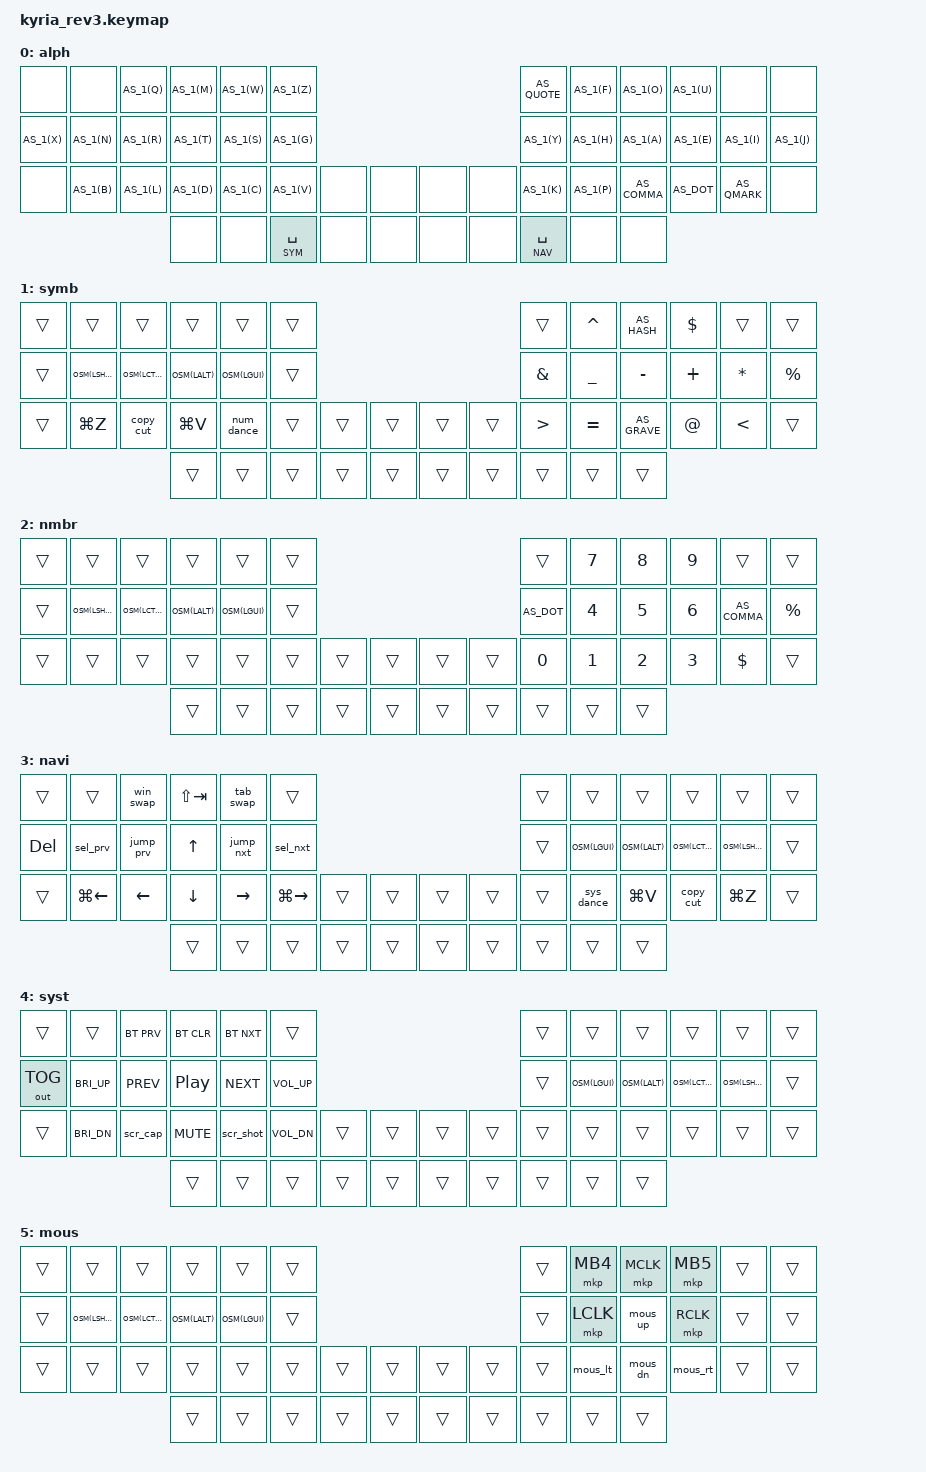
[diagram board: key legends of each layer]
#include <behaviors.dtsi>
#include <behaviors/num_word.dtsi>
#include <behaviors/mouse_keys.dtsi>
#include <dt-bindings/zmk/bt.h>
#include <dt-bindings/zmk/keys.h>
#include <dt-bindings/zmk/mouse.h>
#include <dt-bindings/zmk/outputs.h>

/* Layer Definitions */
#define ALP 0
#define SYM 1
#define NUM 2
#define NAV 3
#define SYS 4
#define MOUSE 5
#define ALL_NM ALP SYM SYS NAV NUM
#define ALL ALL_NM MOUSE
/* ---------------- */

#include "zmk-helpers/helper.h"
#include "includes/key-labels.h"
#include "includes/behaviors.dtsi"  // Requires key-labels.
#include "includes/combos.dtsi"     // Requires behaviors.

/* Initialise Behaviors */
WIN_SWAP(LT2)
TAB_SWAP(LT2)
/* ---------------- */

#define XXX &none
#define ___ &trans
#define AS_COMMA AS_2(SEMI, COMMA)
#define AS_DOT   AS_2(COLON, DOT)
#define AS_QMARK AS_2(EXCL, QMARK)
#define AS_QUOTE AS_2(DQT, SQT)
#define AS_GRAVE AS_2(TILDE, GRAVE)
#define AS_HASH  AS_2(PIPE, HASH)

/* Global Overrides */
&lt {
    flavor="balanced";
    quick-tap-ms=<175>;
    tapping-term-ms=<200>;
    retro-tap;
};

#undef ZMK_MOUSE_DEFAULT_MOVE_VAL // 600
#define ZMK_MOUSE_DEFAULT_MOVE_VAL 6000
#undef ZMK_MOUSE_DEFAULT_SCRL_VAL // 10
#define ZMK_MOUSE_DEFAULT_SCRL_VAL 5

&mmv {
    acceleration-exponent = <2>;      // 1
    time-to-max-speed-ms = <600>;     // 300
};

&msc {
    acceleration-exponent = <2>;      // 0
    time-to-max-speed-ms = <1200>;     // 300
};
/* ---------------- */

ZMK_LAYER(alph,
//  ╭─────────────┬─────────────┬─────────────┬─────────────┬─────────────┬─────────────╮                                                          ╭─────────────┬─────────────┬─────────────┬─────────────┬─────────────┬─────────────╮
      XXX           XXX           AS_1(Q)       AS_1(M)       AS_1(W)       AS_1(Z)                                                                  AS_QUOTE      AS_1(F)       AS_1(O)       AS_1(U)       XXX           XXX
//  ├─────────────┼─────────────┼─────────────┼─────────────┼─────────────┼─────────────┤                                                          ├─────────────┼─────────────┼─────────────┼─────────────┼─────────────┼─────────────┤
      AS_1(X)       AS_1(N)       AS_1(R)       AS_1(T)       AS_1(S)       AS_1(G)                                                                  AS_1(Y)       AS_1(H)       AS_1(A)       AS_1(E)       AS_1(I)       AS_1(J)
//  ├─────────────┼─────────────┼─────────────┼─────────────┼─────────────┼─────────────┼─────────────┬─────────────╮  ╭─────────────┬─────────────┬─────────────┬─────────────┬─────────────┬─────────────┬─────────────┬─────────────┤
      XXX           AS_1(B)       AS_1(L)       AS_1(D)       AS_1(C)       AS_1(V)       XXX           XXX              XXX           XXX           AS_1(K)       AS_1(P)       AS_COMMA      AS_DOT        AS_QMARK      XXX       
//  ╰─────────────┴─────────────┴─────────────┼─────────────┼─────────────┼─────────────┼─────────────┬─────────────┤  ├─────────────┼─────────────┼─────────────┼─────────────┼─────────────┼─────────────┴─────────────┴─────────────╯
                                                XXX           XXX          &lt SYM SPACE  XXX           XXX              XXX           XXX          &lt NAV SPACE   XXX          XXX           
//                                            ╰─────────────┴─────────────┴─────────────┴─────────────┴─────────────╯  ╰─────────────┴─────────────┴─────────────┴─────────────┴─────────────╯
)

ZMK_LAYER(symb,
//  ╭─────────────┬─────────────┬─────────────┬─────────────┬─────────────┬─────────────╮                                                          ╭─────────────┬─────────────┬─────────────┬─────────────┬─────────────┬─────────────╮
      ___           ___           ___           ___           ___           ___                                                                      ___           &kp CARET     AS_HASH       &kp DLLR      ___           ___
//  ├─────────────┼─────────────┼─────────────┼─────────────┼─────────────┼─────────────┤                                                          ├─────────────┼─────────────┼─────────────┼─────────────┼─────────────┼─────────────┤
      ___           OSM(LSHFT)    OSM(LCTRL)    OSM(LALT)     OSM(LGUI)     ___                                                                      &kp AMPS      &kp UNDER     &kp MINUS     &kp PLUS      &kp ASTRK     &kp PRCNT
//  ├─────────────┼─────────────┼─────────────┼─────────────┼─────────────┼─────────────┼─────────────┬─────────────╮  ╭─────────────┬─────────────┬─────────────┬─────────────┬─────────────┬─────────────┬─────────────┬─────────────┤
      ___           &kp LG(Z)     &copy_cut     &kp LG(V)     &num_dance    ___           ___           ___              ___           ___           &kp GT        &kp EQUAL     AS_GRAVE      &kp AT        &kp LT        ___   
//  ╰─────────────┴─────────────┴─────────────┼─────────────┼─────────────┼─────────────┼─────────────┬─────────────┤  ├─────────────┼─────────────┼─────────────┼─────────────┼─────────────┼─────────────┴─────────────┴─────────────╯
                                                ___           ___           ___           ___           ___              ___           ___           ___           ___           ___          
//                                            ╰─────────────┴─────────────┴─────────────┴─────────────┴─────────────╯  ╰─────────────┴─────────────┴─────────────┴─────────────┴─────────────╯
)

ZMK_LAYER(nmbr,
//  ╭─────────────┬─────────────┬─────────────┬─────────────┬─────────────┬─────────────╮                                                          ╭─────────────┬─────────────┬─────────────┬─────────────┬─────────────┬─────────────╮
      ___           ___           ___           ___           ___           ___                                                                      ___           &kp N7        &kp N8        &kp N9        ___           ___
//  ├─────────────┼─────────────┼─────────────┼─────────────┼─────────────┼─────────────┤                                                          ├─────────────┼─────────────┼─────────────┼─────────────┼─────────────┼─────────────┤
      ___           OSM(LSHFT)    OSM(LCTRL)    OSM(LALT)     OSM(LGUI)     ___                                                                      AS_DOT        &kp N4        &kp N5        &kp N6        AS_COMMA      &kp PRCNT
//  ├─────────────┼─────────────┼─────────────┼─────────────┼─────────────┼─────────────┼─────────────┬─────────────╮  ╭─────────────┬─────────────┬─────────────┬─────────────┬─────────────┬─────────────┬─────────────┬─────────────┤
      ___           ___           ___           ___           ___           ___           ___           ___              ___           ___           &kp N0        &kp N1        &kp N2        &kp N3        &kp DLLR      ___       
//  ╰─────────────┴─────────────┴─────────────┼─────────────┼─────────────┼─────────────┼─────────────┬─────────────┤  ├─────────────┼─────────────┼─────────────┼─────────────┼─────────────┼─────────────┴─────────────┴─────────────╯
                                                ___           ___           ___           ___           ___              ___           ___           ___           ___           ___           
//                                            ╰─────────────┴─────────────┴─────────────┴─────────────┴─────────────╯  ╰─────────────┴─────────────┴─────────────┴─────────────┴─────────────╯
)

ZMK_LAYER(navi,
//  ╭─────────────┬─────────────┬─────────────┬─────────────┬─────────────┬─────────────╮                                                          ╭─────────────┬─────────────┬─────────────┬─────────────┬─────────────┬─────────────╮
      ___           ___           &win_swap     &kp LS(TAB)   &tab_swap     ___                                                                      ___           ___           ___           ___           ___           ___
//  ├─────────────┼─────────────┼─────────────┼─────────────┼─────────────┼─────────────┤                                                          ├─────────────┼─────────────┼─────────────┼─────────────┼─────────────┼─────────────┤
      &kp DEL       &sel_prv      &jump_prv     &kp UP        &jump_nxt     &sel_nxt                                                                 ___           OSM(LGUI)     OSM(LALT)     OSM(LCTRL)    OSM(LSHFT)    ___
//  ├─────────────┼─────────────┼─────────────┼─────────────┼─────────────┼─────────────┼─────────────┬─────────────╮  ╭─────────────┬─────────────┬─────────────┬─────────────┬─────────────┬─────────────┬─────────────┬─────────────┤
      ___           &kp LG(LEFT)  &kp LEFT      &kp DOWN      &kp RIGHT     &kp LG(RIGHT) ___           ___              ___           ___           ___           &sys_dance    &kp LG(V)     &copy_cut     &kp LG(Z)     ___       
//  ╰─────────────┴─────────────┴─────────────┼─────────────┼─────────────┼─────────────┼─────────────┬─────────────┤  ├─────────────┼─────────────┼─────────────┼─────────────┼─────────────┼─────────────┴─────────────┴─────────────╯
                                                ___           ___           ___           ___           ___              ___           ___           ___           ___           ___          
//                                            ╰─────────────┴─────────────┴─────────────┴─────────────┴─────────────╯  ╰─────────────┴─────────────┴─────────────┴─────────────┴─────────────╯
)

ZMK_LAYER(syst,
//  ╭─────────────┬─────────────┬─────────────┬─────────────┬─────────────┬─────────────╮                                                          ╭─────────────┬─────────────┬─────────────┬─────────────┬─────────────┬─────────────╮
      ___           ___           &bt BT_PRV    &bt BT_CLR    &bt BT_NXT    ___                                                                      ___           ___           ___           ___           ___           ___
//  ├─────────────┼─────────────┼─────────────┼─────────────┼─────────────┼─────────────┤                                                          ├─────────────┼─────────────┼─────────────┼─────────────┼─────────────┼─────────────┤
      &out OUT_TOG  &kp C_BRI_UP  &kp C_PREV    &kp C_PP      &kp C_NEXT    &kp C_VOL_UP                                                             ___           OSM(LGUI)     OSM(LALT)     OSM(LCTRL)    OSM(LSHFT)    ___
//  ├─────────────┼─────────────┼─────────────┼─────────────┼─────────────┼─────────────┼─────────────┬─────────────╮  ╭─────────────┬─────────────┬─────────────┬─────────────┬─────────────┬─────────────┬─────────────┬─────────────┤
      ___           &kp C_BRI_DN  &scr_cap      &kp C_MUTE    &scr_shot     &kp C_VOL_DN  ___           ___              ___           ___           ___           ___           ___           ___           ___           ___       
//  ╰─────────────┴─────────────┴─────────────┼─────────────┼─────────────┼─────────────┼─────────────┬─────────────┤  ├─────────────┼─────────────┼─────────────┼─────────────┼─────────────┼─────────────┴─────────────┴─────────────╯
                                                ___           ___           ___           ___           ___              ___           ___           ___           ___           ___          
//                                            ╰─────────────┴─────────────┴─────────────┴─────────────┴─────────────╯  ╰─────────────┴─────────────┴─────────────┴─────────────┴─────────────╯
)

ZMK_LAYER(mous,
//  ╭─────────────┬─────────────┬─────────────┬─────────────┬─────────────┬─────────────╮                                                          ╭─────────────┬─────────────┬─────────────┬─────────────┬─────────────┬─────────────╮
      ___           ___           ___           ___           ___           ___                                                                      ___           &mkp MB4      &mkp MCLK     &mkp MB5      ___           ___         
//  ├─────────────┼─────────────┼─────────────┼─────────────┼─────────────┼─────────────┤                                                          ├─────────────┼─────────────┼─────────────┼─────────────┼─────────────┼─────────────┤
      ___           OSM(LSHFT)    OSM(LCTRL)    OSM(LALT)     OSM(LGUI)     ___                                                                      ___           &mkp LCLK     &mous_up      &mkp RCLK     ___           ___         
//  ├─────────────┼─────────────┼─────────────┼─────────────┼─────────────┼─────────────┼─────────────┬─────────────╮  ╭─────────────┬─────────────┬─────────────┬─────────────┬─────────────┬─────────────┬─────────────┬─────────────┤
      ___           ___           ___           ___           ___           ___           ___           ___              ___           ___           ___           &mous_lt      &mous_dn      &mous_rt      ___           ___         
//  ╰─────────────┴─────────────┴─────────────┼─────────────┼─────────────┼─────────────┼─────────────┬─────────────┤  ├─────────────┼─────────────┼─────────────┼─────────────┼─────────────┼─────────────┴─────────────┴─────────────╯
                                                ___           ___           ___           ___           ___              ___           ___           ___           ___           ___           
//                                            ╰─────────────┴─────────────┴─────────────┴─────────────┴─────────────╯  ╰─────────────┴─────────────┴─────────────┴─────────────┴─────────────╯
)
